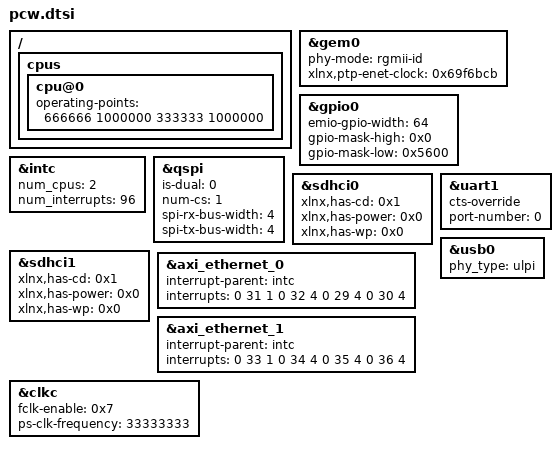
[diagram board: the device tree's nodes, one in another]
/*
 * CAUTION: This file is automatically generated by Xilinx.
 * Version: XSCT 2021.1
 * Today is: Thu May 29 18:24:14 2025
 */


/ {
	cpus {
		cpu@0 {
			operating-points = <666666 1000000 333333 1000000>;
		};
	};
};
&gem0 {
	phy-mode = "rgmii-id";
	status = "okay";
	xlnx,ptp-enet-clock = <0x69f6bcb>;
};
&gpio0 {
	emio-gpio-width = <64>;
	gpio-mask-high = <0x0>;
	gpio-mask-low = <0x5600>;
};
&intc {
	num_cpus = <2>;
	num_interrupts = <96>;
};
&qspi {
	is-dual = <0>;
	num-cs = <1>;
	spi-rx-bus-width = <4>;
	spi-tx-bus-width = <4>;
	status = "okay";
};
&sdhci0 {
	status = "okay";
	xlnx,has-cd = <0x1>;
	xlnx,has-power = <0x0>;
	xlnx,has-wp = <0x0>;
};
&sdhci1 {
	status = "okay";
	xlnx,has-cd = <0x1>;
	xlnx,has-power = <0x0>;
	xlnx,has-wp = <0x0>;
};
&uart1 {
	cts-override ;
	device_type = "serial";
	port-number = <0>;
	status = "okay";
};
&usb0 {
	phy_type = "ulpi";
	status = "okay";
};
&axi_ethernet_0 {
	interrupt-names = "mac_irq", "interrupt", "mm2s_introut", "s2mm_introut";
	interrupt-parent = <&intc>;
	interrupts = <0 31 1 0 32 4 0 29 4 0 30 4>;
};
&axi_ethernet_1 {
	interrupt-names = "mac_irq", "interrupt", "mm2s_introut", "s2mm_introut";
	interrupt-parent = <&intc>;
	interrupts = <0 33 1 0 34 4 0 35 4 0 36 4>;
};
&clkc {
	fclk-enable = <0x7>;
	ps-clk-frequency = <33333333>;
};
